AUTOSAR XML (schema 4-2-2)
package /Components
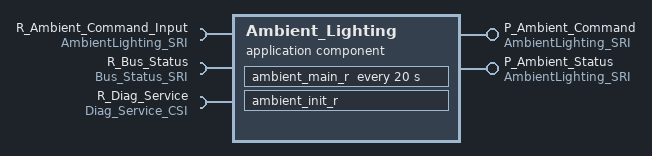
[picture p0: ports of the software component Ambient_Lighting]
  application sw component type Ambient_Lighting
    provide port P_Ambient_Command: provided-interface=AmbientLighting_SRI
    provide port P_Ambient_Status: provided-interface=AmbientLighting_SRI
    require port R_Ambient_Command_Input: required-interface=AmbientLighting_SRI
    require port R_Bus_Status: required-interface=Bus_Status_SRI
    require port R_Diag_Service: required-interface=Diag_Service_CSI
    behavior Ambient_Lighting_InternalBehavior
      init event Ambient_Init: start-on-event=ambient_init_r
      timing event Ambient_Main_Cycle: start-on-event=ambient_main_r, period=20
      runnable ambient_init_r
        data-send-points:
          access tx_initial_ambient_status: accessed-variable=P_Ambient_Status.ambient_status
        sync call scp_get_update_status_init: operation=R_Diag_Service.GetUpdateStatus, timeout=2000
      runnable ambient_main_r: minimum-start-interval=20
        data-receive-point-by-arguments:
          5 x access:
            rx_ambient_color_cmd_access: accessed-variable=R_Ambient_Command_Input.ambient_color_cmd
            rx_ambient_brightness_cmd_access: accessed-variable=R_Ambient_Command_Input.ambient_brightness_cmd
            rx_bus_online_access: accessed-variable=R_Bus_Status.bus_online
            rx_bus_error_count_access: accessed-variable=R_Bus_Status.bus_error_count
            rx_bus_load_access: accessed-variable=R_Bus_Status.bus_load
        data-send-points:
          access tx_ambient_color_cmd_access: accessed-variable=P_Ambient_Command.ambient_color_cmd
          access tx_ambient_brightness_cmd_access: accessed-variable=P_Ambient_Command.ambient_brightness_cmd
          access tx_ambient_status_access: accessed-variable=P_Ambient_Status.ambient_status
        sync call scp_get_update_status_main: operation=R_Diag_Service.GetUpdateStatus, timeout=2000
